# EZR32LG330F128R60 register map
File version: 4.0.0
CPU: CM3 r2p1, little endian, MPU, no FPU, 3 interrupt priority bits
Registers are 32-bit, read-write, reset 0x0 unless marked. A register's access mark holds for its fields unless they carry their own. Offsets are from the block's base; [hi:lo] are bit positions; {n}, {i} and the like mark numbered series.

## PCNT0
Base 0x40086000
Same registers: PCNT1 0x40086400, PCNT2 0x40086800
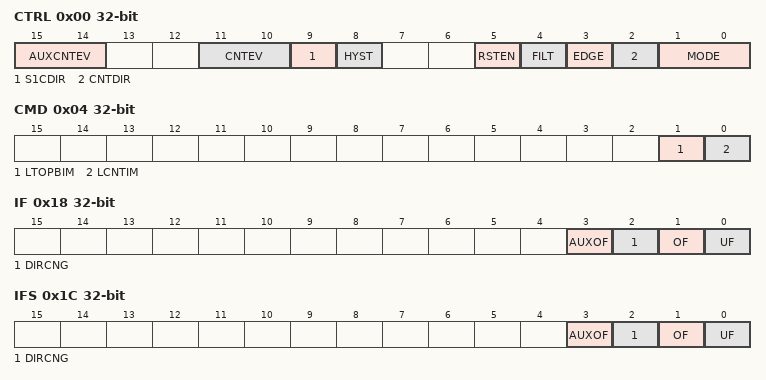
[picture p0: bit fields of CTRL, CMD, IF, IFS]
0x00 CTRL — Control Register
  [15:14] AUXCNTEV — Controls when the auxiliary counter counts
    0=NONE (Never counts.); 1=UP (Counts up on up-count events.); 2=DOWN (Counts up on down-count events.); 3=BOTH (Counts up on both up-count and down-count events.)
  [11:10] CNTEV — Controls when the counter counts
    0=BOTH (Counts up on up-count and down on down-count events.); 1=UP (Only counts up on up-count events.); 2=DOWN (Only counts down on down-count events.); 3=NONE (Never counts.)
  [9] S1CDIR — Count direction determined by S1
  [8] HYST — Enable Hysteresis
  [5] RSTEN — Enable PCNT Clock Domain Reset
  [4] FILT — Enable Digital Pulse Width Filter
  [3] EDGE — Edge Select
  [2] CNTDIR — Non-Quadrature Mode Counter Direction Control
  [1:0] MODE — Mode Select
    0=DISABLE (The module is disabled.); 1=OVSSINGLE (Single input LFACLK oversampling mode (available in EM0-EM2).); 2=EXTCLKSINGLE (Externally clocked single input counter mode (available in EM0-EM3).); 3=EXTCLKQUAD (Externally clocked quadrature decoder mode (available in EM0-EM3).)
0x04 CMD wo — Command Register
  [1] LTOPBIM — Load TOPB Immediately
  [0] LCNTIM — Load CNT Immediately
0x08 STATUS ro
  [0] DIR — Current Counter Direction
0x0C CNT ro — Counter Value Register
  [15:0] CNT — Counter Value
0x10 TOP ro reset 0xFF — Top Value Register
  [15:0] TOP — Counter Top Value
0x14 TOPB reset 0xFF — Top Value Buffer Register
  [15:0] TOPB — Counter Top Buffer
0x18 IF ro — Interrupt Flag Register
  [3] AUXOF — Overflow Interrupt Read Flag
  [2] DIRCNG — Direction Change Detect Interrupt Flag
  [1] OF — Overflow Interrupt Read Flag
  [0] UF — Underflow Interrupt Read Flag
0x1C IFS wo — Interrupt Flag Set Register
  [3] AUXOF — Auxiliary Overflow Interrupt Set
  [2] DIRCNG — Direction Change Detect Interrupt Set
  [1] OF — Overflow Interrupt Set
  [0] UF — Underflow interrupt set
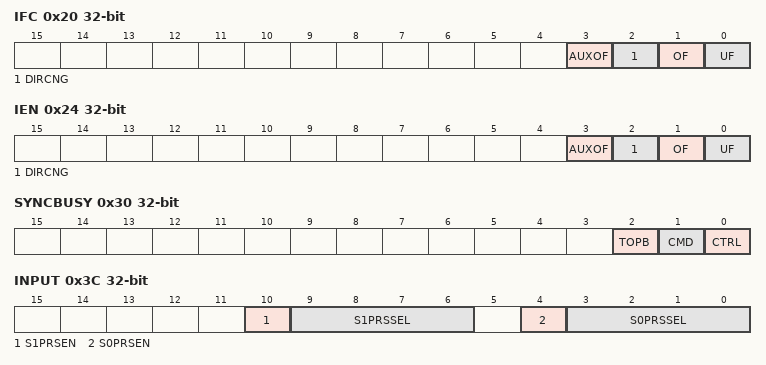
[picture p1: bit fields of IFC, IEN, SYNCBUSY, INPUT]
0x20 IFC wo — Interrupt Flag Clear Register
  [3] AUXOF — Auxiliary Overflow Interrupt Clear
  [2] DIRCNG — Direction Change Detect Interrupt Clear
  [1] OF — Overflow Interrupt Clear
  [0] UF — Underflow Interrupt Clear
0x24 IEN — Interrupt Enable Register
  [3] AUXOF — Auxiliary Overflow Interrupt Enable
  [2] DIRCNG — Direction Change Detect Interrupt Enable
  [1] OF — Overflow Interrupt Enable
  [0] UF — Underflow Interrupt Enable
0x28 ROUTE — I/O Routing Register
  [10:8] LOCATION — I/O Location
    {v}=LOC{v} (Location {v}) (v=0..3)
0x2C FREEZE
  [0] REGFREEZE — Register Update Freeze
0x30 SYNCBUSY ro — Synchronization Busy Register
  [2] TOPB — TOPB Register Busy
  [1] CMD — CMD Register Busy
  [0] CTRL — CTRL Register Busy
0x38 AUXCNT — Auxiliary Counter Value Register
  [15:0] AUXCNT — Auxiliary Counter Value
0x3C INPUT — PCNT Input Register
  [10] S1PRSEN — S1IN PRS Enable
  [9:6] S1PRSSEL — S1IN PRS Channel Select
    {v}=PRSCH{v} (PRS Channel {v} selected.) (v=0..11)
  [4] S0PRSEN — S0IN PRS Enable
  [3:0] S0PRSSEL — S0IN PRS Channel Select
    {v}=PRSCH{v} (PRS Channel {v} selected.) (v=0..11)

## VCMP
Base 0x40000000
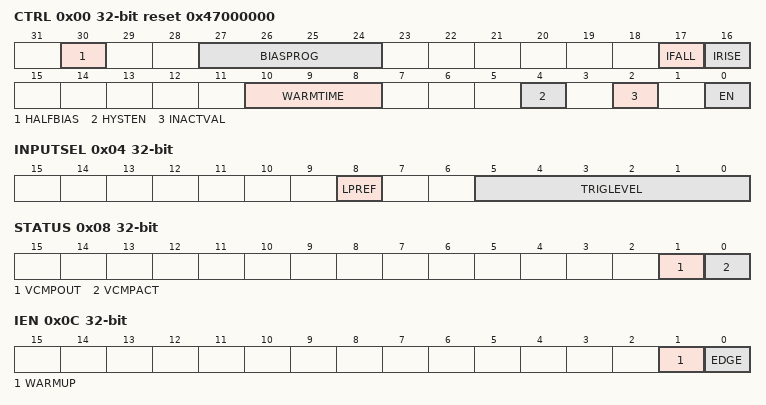
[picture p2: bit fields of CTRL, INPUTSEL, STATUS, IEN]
0x00 CTRL reset 0x47000000 — Control Register
  [30] HALFBIAS — Half Bias Current
  [27:24] BIASPROG — VCMP Bias Programming Value
  [17] IFALL — Falling Edge Interrupt Sense
  [16] IRISE — Rising Edge Interrupt Sense
  [10:8] WARMTIME — Warm-Up Time
    0=4CYCLES (4 HFPERCLK cycles); 1=8CYCLES (8 HFPERCLK cycles); 2=16CYCLES (16 HFPERCLK cycles); 3=32CYCLES (32 HFPERCLK cycles); 4=64CYCLES (64 HFPERCLK cycles); 5=128CYCLES (128 HFPERCLK cycles); 6=256CYCLES (256 HFPERCLK cycles); 7=512CYCLES (512 HFPERCLK cycles)
  [4] HYSTEN — Hysteresis Enable
  [2] INACTVAL — Inactive Value
  [0] EN — Voltage Supply Comparator Enable
0x04 INPUTSEL — Input Selection Register
  [8] LPREF — Low Power Reference
  [5:0] TRIGLEVEL — Trigger Level
0x08 STATUS ro
  [1] VCMPOUT — Voltage Supply Comparator Output
  [0] VCMPACT — Voltage Supply Comparator Active
0x0C IEN — Interrupt Enable Register
  [1] WARMUP — Warm-up Interrupt Enable
  [0] EDGE — Edge Trigger Interrupt Enable
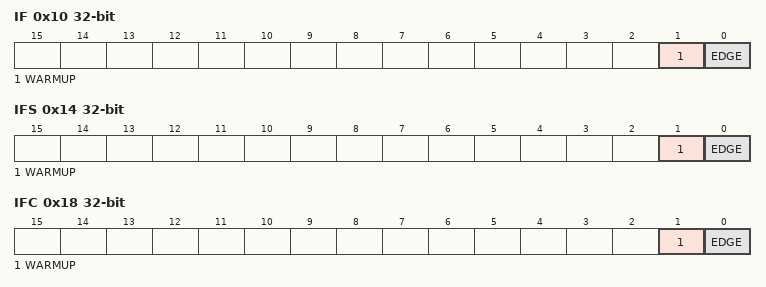
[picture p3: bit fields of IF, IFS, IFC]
0x10 IF ro — Interrupt Flag Register
  [1] WARMUP — Warm-up Interrupt Flag
  [0] EDGE — Edge Triggered Interrupt Flag
0x14 IFS wo — Interrupt Flag Set Register
  [1] WARMUP — Warm-up Interrupt Flag Set
  [0] EDGE — Edge Triggered Interrupt Flag Set
0x18 IFC wo — Interrupt Flag Clear Register
  [1] WARMUP — Warm-up Interrupt Flag Clear
  [0] EDGE — Edge Triggered Interrupt Flag Clear

## PRS
Base 0x400CC000
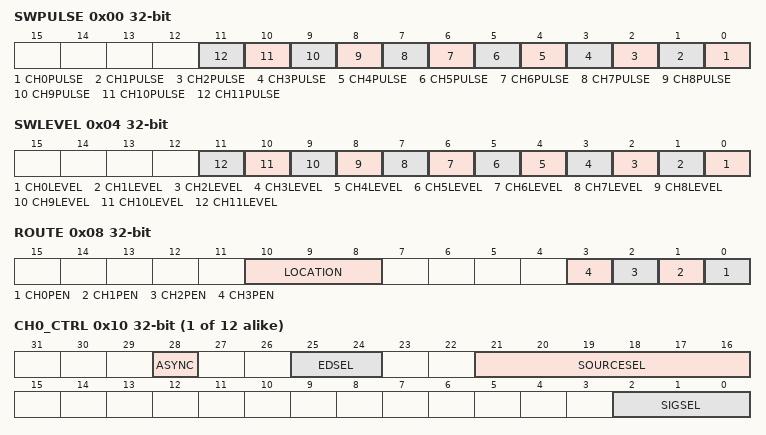
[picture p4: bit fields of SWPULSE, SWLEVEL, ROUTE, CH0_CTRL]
0x00 SWPULSE wo — Software Pulse Register
  [n] CH{n}PULSE (n=0..11) — Channel {n} Pulse Generation
0x04 SWLEVEL — Software Level Register
  [n] CH{n}LEVEL (n=0..11) — Channel {n} Software Level
0x08 ROUTE — I/O Routing Register
  [10:8] LOCATION — I/O Location
    0=LOC0 (Location 0); 1=LOC1 (Location 1)
  [n] CH{n}PEN (n=0..3) — CH{n} Pin Enable
{0x10+4i} CH{i}_CTRL (i=0..11) — Channel Control Register
  [28] ASYNC — Asynchronous reflex
  [25:24] EDSEL — Edge Detect Select
    0=OFF (Signal is left as it is); 1=POSEDGE (A one HFPERCLK cycle pulse is generated for every positive edge of the incoming signal); 2=NEGEDGE (A one HFPERCLK clock cycle pulse is generated for every negative edge of the incoming signal); 3=BOTHEDGES (A one HFPERCLK clock cycle pulse is generated for every edge of the incoming signal)
  [21:16] SOURCESEL — Source Select
    0=NONE (No source selected); 1=VCMP (Voltage Comparator); 2=ACMP0 (Analog Comparator 0); 3=ACMP1 (Analog Comparator 1); 6=DAC0 (Digital to Analog Converter 0); 8=ADC0 (Analog to Digital Converter 0); 16=USARTRF0 (Universal Synchronous/Asynchronous Receiver/Transmitter 0); 17=USART1 (Universal Synchronous/Asynchronous Receiver/Transmitter 1); 18=USART2 (Universal Synchronous/Asynchronous Receiver/Transmitter 2); {v}=TIMER{v-28} (v=28..31); 36=USB (Universal Serial Bus Interface); 40=RTC (Real-Time Counter); 41=UART0 (Universal Asynchronous Receiver/Transmitter 0); 42=UART1 (Universal Asynchronous Receiver/Transmitter 1); 48=GPIOL (General purpose Input/Output); 49=GPIOH (General purpose Input/Output); 52=LETIMER0 (Low Energy Timer 0); 55=BURTC (Backup RTC); 57=LESENSEL (Low Energy Sensor Interface); 58=LESENSEH (Low Energy Sensor Interface); 59=LESENSED (Low Energy Sensor Interface)
  [2:0] SIGSEL — Signal Select

## WDOG
Base 0x40088000
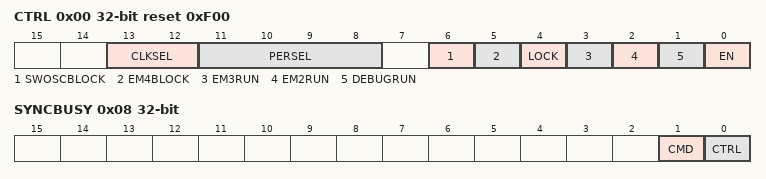
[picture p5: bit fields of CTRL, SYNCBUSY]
0x00 CTRL reset 0xF00 — Control Register
  [13:12] CLKSEL — Watchdog Clock Select
    0=ULFRCO; 1=LFRCO; 2=LFXO
  [11:8] PERSEL — Watchdog Timeout Period Select
  [6] SWOSCBLOCK — Software Oscillator Disable Block
  [5] EM4BLOCK — Energy Mode 4 Block
  [4] LOCK — Configuration lock
  [3] EM3RUN — Energy Mode 3 Run Enable
  [2] EM2RUN — Energy Mode 2 Run Enable
  [1] DEBUGRUN — Debug Mode Run Enable
  [0] EN — Watchdog Timer Enable
0x04 CMD wo — Command Register
  [0] CLEAR — Watchdog Timer Clear
0x08 SYNCBUSY ro — Synchronization Busy Register
  [1] CMD — CMD Register Busy
  [0] CTRL — CTRL Register Busy

## Notices in the file
# License
Copyright 2021 Silicon Laboratories Inc. www.silabs.com
SPDX-License-Identifier: Zlib
The licensor of this software is Silicon Laboratories Inc.
This software is provided 'as-is', without any express or implied
warranty. In no event will the authors be held liable for any damages
arising from the use of this software.
Permission is granted to anyone to use this software for any purpose,
including commercial applications, and to alter it and redistribute it
freely, subject to the following restrictions:
1. The origin of this software must not be misrepresented; you must not
claim that you wrote the original software. If you use this software
in a product, an acknowledgment in the product documentation would be
appreciated but is not required.
2. Altered source versions must be plainly marked as such, and must not be
misrepresented as being the original software.
3. This notice may not be removed or altered from any source distribution.
